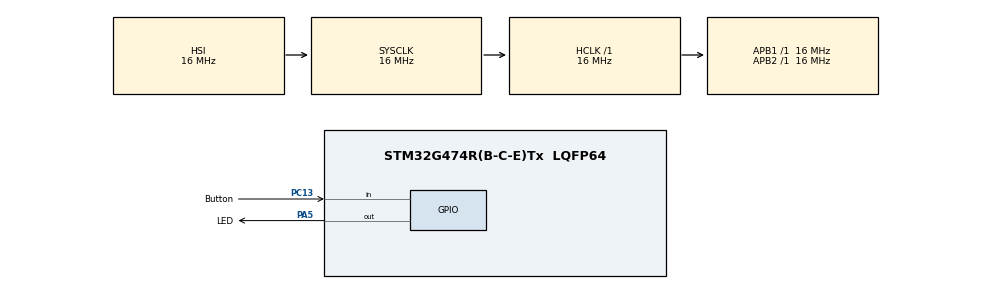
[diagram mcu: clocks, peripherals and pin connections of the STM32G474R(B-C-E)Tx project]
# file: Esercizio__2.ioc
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Mcu.Family=STM32G4
Mcu.Name=STM32G474R(B-C-E)Tx
Mcu.Package=LQFP64
NVIC.PriorityGroup=NVIC_PRIORITYGROUP_4
PA5.GPIO_Label=LED
PA5.Signal=GPIO_Output
PC13.GPIO_Label=Button
PC13.Signal=GPIO_Input
ProjectManager.HeapSize=0x200
ProjectManager.StackSize=0x400
ProjectManager.TargetToolchain=STM32CubeIDE
RCC.AHBFreq_Value=16000000
RCC.APB1Freq_Value=16000000
RCC.APB1TimFreq_Value=16000000
RCC.APB2Freq_Value=16000000
RCC.APB2TimFreq_Value=16000000
RCC.CortexFreq_Value=16000000
RCC.EXTERNAL_CLOCK_VALUE=12288000
RCC.HCLKFreq_Value=16000000
RCC.HSE_VALUE=8000000
RCC.HSI48_VALUE=48000000
RCC.HSI_VALUE=16000000
RCC.LSE_VALUE=32768
RCC.SYSCLKFreq_VALUE=16000000
RCC.USBFreq_Value=64000000
RCC.VCOOutputFreq_Value=128000000
board=custom

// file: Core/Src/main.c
/* USER CODE BEGIN Header */
/**
  ******************************************************************************
  * @file           : main.c
  * @brief          : Main program body
  ******************************************************************************
  * @attention
  *
  * Copyright (c) 2025 STMicroelectronics.
  * All rights reserved.
  *
  * This software is licensed under terms that can be found in the LICENSE file
  * in the root directory of this software component.
  * If no LICENSE file comes with this software, it is provided AS-IS.
  *
  ******************************************************************************
  */
/* USER CODE END Header */
#include "main.h"
#include "gpio.h"

void SystemClock_Config(void);

/* USER CODE BEGIN 0 */

typedef enum{
	ONE_HZ = 1,
	TWO_HZ,
	FOUR_HZ
}State;

State currentState = ONE_HZ;
int sleepTime = 10;

void changeFrequency(State);

/* USER CODE END 0 */

int main(void)
{

  /* MCU Configuration--------------------------------------------------------*/

  /* Reset of all peripherals, Initializes the Flash interface and the Systick. */
  HAL_Init();

  /* Configure the system clock */
  SystemClock_Config();

  /* Initialize all configured peripherals */
  MX_GPIO_Init();

  /* Infinite loop */
  while (1)
  {

    /* USER CODE BEGIN 3 */
	  if(HAL_GPIO_ReadPin(Button_GPIO_Port, Button_Pin) == GPIO_PIN_SET)
		  changeFrequency(currentState);

	  HAL_Delay(sleepTime);
	  HAL_GPIO_TogglePin(LED_GPIO_Port, LED_Pin);

  }
  /* USER CODE END 3 */
}

void SystemClock_Config(void)
{
  RCC_OscInitTypeDef RCC_OscInitStruct = {0};
  RCC_ClkInitTypeDef RCC_ClkInitStruct = {0};

  /** Configure the main internal regulator output voltage
  */
  HAL_PWREx_ControlVoltageScaling(PWR_REGULATOR_VOLTAGE_SCALE1);

  /** Initializes the RCC Oscillators according to the specified parameters
  * in the RCC_OscInitTypeDef structure.
  */
  RCC_OscInitStruct.OscillatorType = RCC_OSCILLATORTYPE_HSI;
  RCC_OscInitStruct.HSIState = RCC_HSI_ON;
  RCC_OscInitStruct.HSICalibrationValue = RCC_HSICALIBRATION_DEFAULT;
  RCC_OscInitStruct.PLL.PLLState = RCC_PLL_NONE;
  if (HAL_RCC_OscConfig(&RCC_OscInitStruct) != HAL_OK)
  {
    Error_Handler();
  }

  /** Initializes the CPU, AHB and APB buses clocks
  */
  RCC_ClkInitStruct.ClockType = RCC_CLOCKTYPE_HCLK|RCC_CLOCKTYPE_SYSCLK
                              |RCC_CLOCKTYPE_PCLK1|RCC_CLOCKTYPE_PCLK2;
  RCC_ClkInitStruct.SYSCLKSource = RCC_SYSCLKSOURCE_HSI;
  RCC_ClkInitStruct.AHBCLKDivider = RCC_SYSCLK_DIV1;
  RCC_ClkInitStruct.APB1CLKDivider = RCC_HCLK_DIV1;
  RCC_ClkInitStruct.APB2CLKDivider = RCC_HCLK_DIV1;

  if (HAL_RCC_ClockConfig(&RCC_ClkInitStruct, FLASH_LATENCY_0) != HAL_OK)
  {
    Error_Handler();
  }
}

/* USER CODE BEGIN 4 */

void changeFrequency(State state){
	if (state == ONE_HZ){
		sleepTime =  500;
		currentState = TWO_HZ;
	}
	else if (state == TWO_HZ){
		sleepTime = 250;
		currentState = FOUR_HZ;
	}
	else if (state == FOUR_HZ){
		sleepTime = 1000;
		currentState = ONE_HZ;
	}

}

/* USER CODE END 4 */

void Error_Handler(void)
{
  __disable_irq();
  while (1)
  {
  }
}
